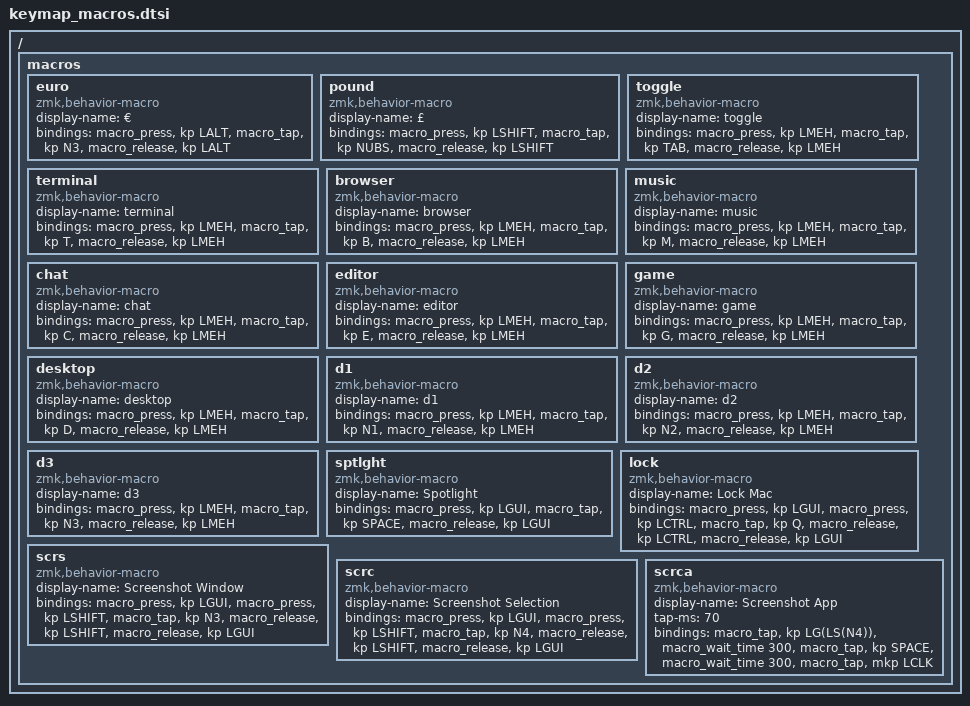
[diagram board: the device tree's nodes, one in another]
/ {
    macros {
        // currencies
        euro: euro {
            display-name = "€";
            compatible = "zmk,behavior-macro";
            #binding-cells = <0>;
            bindings
                = <&macro_press &kp LALT>
                , <&macro_tap &kp N3>
                , <&macro_release &kp LALT>
                ;
        };
        pound: pound {
            display-name = "£";
            compatible = "zmk,behavior-macro";
            #binding-cells = <0>;
            bindings
                = <&macro_press &kp LSHIFT>
                , <&macro_tap &kp NUBS>
                , <&macro_release &kp LSHIFT>
                ;
        };

        // AEROSPACE WORKSPACES
        toggle: toggle {
            display-name = "toggle";
            compatible = "zmk,behavior-macro";
            #binding-cells = <0>;
            bindings
                = <&macro_press &kp LMEH>
                , <&macro_tap &kp TAB>
                , <&macro_release &kp LMEH>
                ;
        };
        terminal: terminal {
            display-name = "terminal";
            compatible = "zmk,behavior-macro";
            #binding-cells = <0>;
            bindings
                = <&macro_press &kp LMEH>
                , <&macro_tap &kp T>
                , <&macro_release &kp LMEH>
                ;
        };
        browser: browser {
            display-name = "browser";
            compatible = "zmk,behavior-macro";
            #binding-cells = <0>;
            bindings
                = <&macro_press &kp LMEH>
                , <&macro_tap &kp B>
                , <&macro_release &kp LMEH>
                ;
        };
        music: music {
            display-name = "music";
            compatible = "zmk,behavior-macro";
            #binding-cells = <0>;
            bindings
                = <&macro_press &kp LMEH>
                , <&macro_tap &kp M>
                , <&macro_release &kp LMEH>
                ;
        };
        chat: chat {
            display-name = "chat";
            compatible = "zmk,behavior-macro";
            #binding-cells = <0>;
            bindings
                = <&macro_press &kp LMEH>
                , <&macro_tap &kp C>
                , <&macro_release &kp LMEH>
                ;
        };
        editor: editor {
            display-name = "editor";
            compatible = "zmk,behavior-macro";
            #binding-cells = <0>;
            bindings
                = <&macro_press &kp LMEH>
                , <&macro_tap &kp E>
                , <&macro_release &kp LMEH>
                ;
        };
        game: game {
            display-name = "game";
            compatible = "zmk,behavior-macro";
            #binding-cells = <0>;
            bindings
                = <&macro_press &kp LMEH>
                , <&macro_tap &kp G>
                , <&macro_release &kp LMEH>
                ;
        };
        desktop: desktop {
            display-name = "desktop";
            compatible = "zmk,behavior-macro";
            #binding-cells = <0>;
            bindings
                = <&macro_press &kp LMEH>
                , <&macro_tap &kp D>
                , <&macro_release &kp LMEH>
                ;
        };
        d1: d1 {
            display-name = "d1";
            compatible = "zmk,behavior-macro";
            #binding-cells = <0>;
            bindings
                = <&macro_press &kp LMEH>
                , <&macro_tap &kp N1>
                , <&macro_release &kp LMEH>
                ;
        };
        d2: d2 {
            display-name = "d2";
            compatible = "zmk,behavior-macro";
            #binding-cells = <0>;
            bindings
                = <&macro_press &kp LMEH>
                , <&macro_tap &kp N2>
                , <&macro_release &kp LMEH>
                ;
        };
        d3: d3 {
            display-name = "d3";
            compatible = "zmk,behavior-macro";
            #binding-cells = <0>;
            bindings
                = <&macro_press &kp LMEH>
                , <&macro_tap &kp N3>
                , <&macro_release &kp LMEH>
                ;
        };

        // SYSTEM
        sptlght: sptlght {
            display-name = "Spotlight";
            compatible = "zmk,behavior-macro";
            #binding-cells = <0>;
            bindings
                = <&macro_press &kp LGUI>
                , <&macro_tap &kp SPACE>
                , <&macro_release &kp LGUI>
                ;
        };
        lock: lock {
            display-name = "Lock Mac";
            compatible = "zmk,behavior-macro";
            #binding-cells = <0>;
            bindings
                = <&macro_press &kp LGUI>
                , <&macro_press &kp LCTRL>
                , <&macro_tap &kp Q>
                , <&macro_release &kp LCTRL>
                , <&macro_release &kp LGUI>
                ;
        };
        scrs: scrs {
            display-name = "Screenshot Window";
            compatible = "zmk,behavior-macro";
            #binding-cells = <0>;
            bindings
                = <&macro_press &kp LGUI>
                , <&macro_press &kp LSHIFT>
                , <&macro_tap &kp N3>
                , <&macro_release &kp LSHIFT>
                , <&macro_release &kp LGUI>
                ;
        };
        scrc: scrc {
            display-name = "Screenshot Selection";
            compatible = "zmk,behavior-macro";
            #binding-cells = <0>;
            bindings
                = <&macro_press &kp LGUI>
                , <&macro_press &kp LSHIFT>
                , <&macro_tap &kp N4>
                , <&macro_release &kp LSHIFT>
                , <&macro_release &kp LGUI>
                ;
        };        
        // MacOS Screenshot Current App
        scrca: scrca {
            display-name = "Screenshot App";
            compatible = "zmk,behavior-macro";
            #binding-cells = <0>;
            tap-ms = <70>;
            bindings
                = <&macro_tap &kp LG(LS(N4))>
                , <&macro_wait_time 300>
                , <&macro_tap &kp SPACE>
                , <&macro_wait_time 300>
                , <&macro_tap &mkp LCLK>
                ;
        };
    };
};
